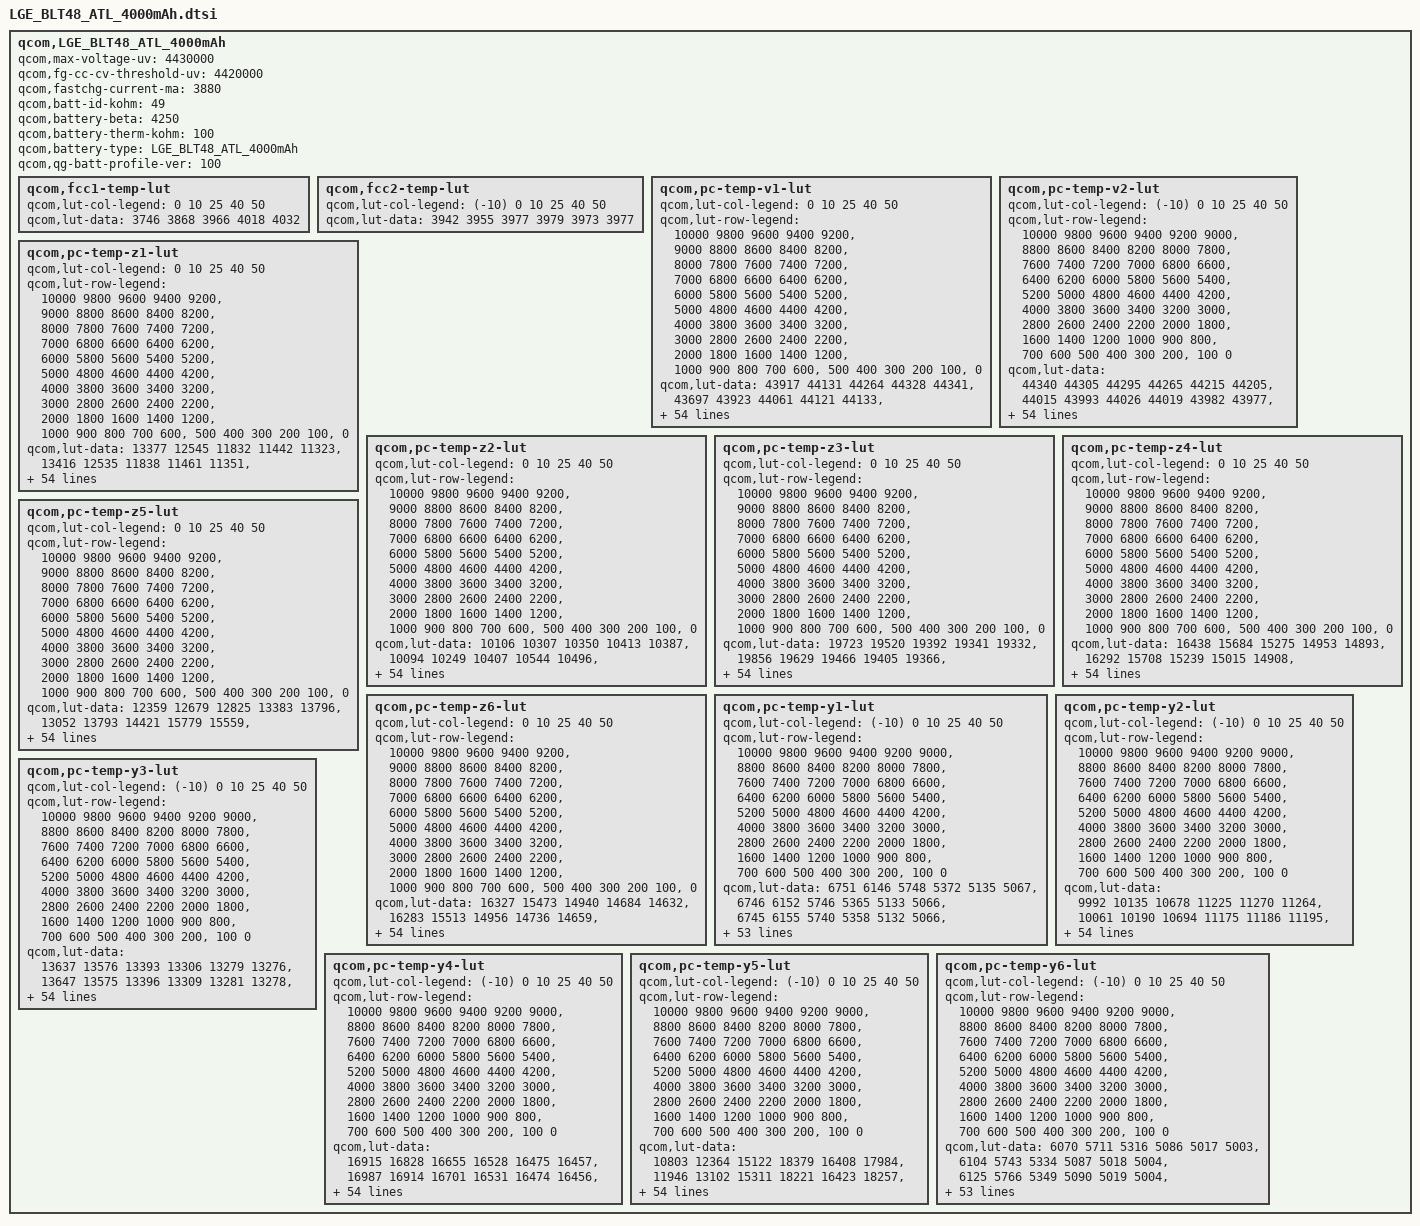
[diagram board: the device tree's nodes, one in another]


qcom,LGE_BLT48_ATL_4000mAh {
    /* 4895688_LGE_ATL_4500mAh_averaged_MasterSlave_Nov23rd2020 */
    qcom,max-voltage-uv = <4430000>;
    qcom,fg-cc-cv-threshold-uv = <4420000>;
    qcom,fastchg-current-ma = <3880>;
    qcom,batt-id-kohm = <49>;
    qcom,battery-beta = <4250>;
    qcom,battery-therm-kohm = <100>;
    qcom,battery-type = "LGE_BLT48_ATL_4000mAh";
    qcom,qg-batt-profile-ver = <100>;

	qcom,fcc1-temp-lut {
		qcom,lut-col-legend = <0 10 25 40 50>;
		qcom,lut-data = <3746 3868 3966 4018 4032>;
	};

	qcom,fcc2-temp-lut {
		qcom,lut-col-legend = <(-10) 0 10 25 40 50>;
		qcom,lut-data = <3942 3955 3977 3979 3973 3977>;
	};

	qcom,pc-temp-v1-lut {
		qcom,lut-col-legend = <0 10 25 40 50>;
		qcom,lut-row-legend = <10000 9800 9600 9400 9200>,
			<9000 8800 8600 8400 8200>,
			<8000 7800 7600 7400 7200>,
			<7000 6800 6600 6400 6200>,
			<6000 5800 5600 5400 5200>,
			<5000 4800 4600 4400 4200>,
			<4000 3800 3600 3400 3200>,
			<3000 2800 2600 2400 2200>,
			<2000 1800 1600 1400 1200>,
			<1000 900 800 700 600>,
			<500 400 300 200 100>,
			<0>;
		qcom,lut-data = <43917 44131 44264 44328 44341>,
			<43697 43923 44061 44121 44133>,
			<43472 43713 43854 43925 43935>,
			<43244 43499 43646 43723 43734>,
			<43013 43274 43434 43516 43527>,
			<42780 43038 43211 43301 43313>,
			<42545 42799 42974 43071 43088>,
			<42309 42559 42732 42831 42853>,
			<42079 42318 42489 42588 42613>,
			<41852 42080 42242 42343 42368>,
			<41630 41844 42000 42099 42122>,
			<41413 41613 41761 41857 41882>,
			<41200 41390 41527 41617 41645>,
			<40996 41174 41298 41384 41412>,
			<40799 40963 41075 41158 41182>,
			<40606 40760 40861 40939 40958>,
			<40407 40563 40655 40726 40743>,
			<40206 40374 40457 40520 40535>,
			<40023 40190 40276 40325 40338>,
			<39869 40009 40103 40147 40159>,
			<39728 39830 39905 39961 39977>,
			<39577 39650 39648 39726 39754>,
			<39415 39439 39393 39466 39505>,
			<39249 39170 39200 39257 39292>,
			<39077 38946 39037 39092 39116>,
			<38898 38827 38903 38947 38962>,
			<38751 38743 38797 38818 38826>,
			<38648 38667 38703 38702 38706>,
			<38564 38595 38610 38597 38596>,
			<38496 38528 38518 38499 38497>,
			<38443 38465 38438 38410 38407>,
			<38396 38404 38365 38329 38321>,
			<38354 38349 38301 38255 38242>,
			<38317 38297 38243 38188 38169>,
			<38280 38251 38193 38129 38107>,
			<38246 38209 38143 38072 38044>,
			<38210 38174 38096 38013 37973>,
			<38164 38132 38046 37952 37896>,
			<38098 38061 37977 37879 37812>,
			<38015 37963 37883 37789 37721>,
			<37912 37855 37778 37687 37619>,
			<37780 37734 37660 37572 37499>,
			<37629 37591 37524 37439 37363>,
			<37463 37417 37357 37274 37203>,
			<37329 37262 37201 37126 37060>,
			<37223 37160 37098 37031 36968>,
			<37190 37132 37072 37008 36949>,
			<37160 37104 37055 36994 36933>,
			<37128 37078 37033 36976 36915>,
			<37079 37040 36998 36932 36867>,
			<36908 36855 36785 36698 36611>,
			<36480 36420 36358 36268 36179>,
			<35913 35853 35793 35700 35611>,
			<35146 35078 35022 34927 34837>,
			<33897 33841 33828 33736 33651>,
			<30000 30000 30000 30000 30000>;
	};

	qcom,pc-temp-v2-lut {
		qcom,lut-col-legend = <(-10) 0 10 25 40 50>;
		qcom,lut-row-legend = <10000 9800 9600 9400 9200 9000>,
			<8800 8600 8400 8200 8000 7800>,
			<7600 7400 7200 7000 6800 6600>,
			<6400 6200 6000 5800 5600 5400>,
			<5200 5000 4800 4600 4400 4200>,
			<4000 3800 3600 3400 3200 3000>,
			<2800 2600 2400 2200 2000 1800>,
			<1600 1400 1200 1000 900 800>,
			<700 600 500 400 300 200>,
			<100 0>;
		qcom,lut-data = <44340 44305 44295 44265 44215 44205>,
			<44015 43993 44026 44019 43982 43977>,
			<43719 43705 43770 43783 43753 43753>,
			<43456 43446 43533 43557 43532 43534>,
			<43227 43217 43314 43343 43319 43322>,
			<43001 42987 43092 43125 43101 43104>,
			<42756 42740 42852 42890 42869 42873>,
			<42506 42486 42607 42648 42629 42634>,
			<42269 42236 42360 42406 42389 42395>,
			<42051 41992 42111 42163 42146 42153>,
			<41820 41743 41865 41921 41906 41913>,
			<41526 41460 41624 41682 41669 41676>,
			<41204 41173 41387 41447 41436 41443>,
			<40975 40988 41161 41216 41208 41214>,
			<40841 40887 40944 40992 40985 40990>,
			<40696 40774 40738 40774 40768 40772>,
			<40415 40524 40550 40565 40560 40564>,
			<40011 40155 40367 40362 40358 40362>,
			<39689 39856 40147 40169 40164 40169>,
			<39462 39634 39867 39990 39983 39990>,
			<39264 39430 39593 39797 39790 39799>,
			<39070 39218 39363 39545 39548 39560>,
			<38886 39010 39156 39265 39282 39299>,
			<38717 38817 38970 39049 39072 39091>,
			<38552 38633 38804 38882 38907 38926>,
			<38407 38465 38654 38739 38766 38782>,
			<38302 38312 38522 38611 38641 38655>,
			<38220 38172 38402 38497 38531 38542>,
			<38147 38079 38282 38391 38428 38438>,
			<38080 38024 38153 38288 38331 38341>,
			<38018 37981 38042 38195 38242 38252>,
			<37957 37936 37960 38112 38162 38170>,
			<37899 37894 37894 38036 38090 38094>,
			<37838 37849 37842 37964 38015 38016>,
			<37773 37802 37806 37896 37938 37936>,
			<37706 37752 37770 37828 37856 37848>,
			<37634 37698 37729 37753 37760 37741>,
			<37558 37641 37684 37673 37652 37618>,
			<37478 37574 37623 37592 37552 37508>,
			<37392 37493 37538 37514 37464 37415>,
			<37304 37398 37434 37429 37374 37322>,
			<37223 37288 37314 37323 37269 37216>,
			<37148 37157 37173 37198 37150 37098>,
			<37074 37022 37018 37046 37009 36956>,
			<36998 36889 36877 36922 36894 36846>,
			<36917 36790 36781 36861 36847 36803>,
			<36866 36759 36747 36843 36836 36791>,
			<36811 36726 36712 36824 36820 36776>,
			<36742 36690 36665 36791 36797 36751>,
			<36654 36622 36570 36713 36723 36665>,
			<36513 36449 36354 36472 36471 36388>,
			<36242 36034 35940 36003 35991 35906>,
			<35773 35380 35303 35369 35373 35281>,
			<35001 34371 34346 34494 34527 34421>,
			<33630 32548 32758 33099 33306 33190>,
			<31039 29548 29509 29507 29507 29506>;
	};

	qcom,pc-temp-z1-lut {
		qcom,lut-col-legend = <0 10 25 40 50>;
		qcom,lut-row-legend = <10000 9800 9600 9400 9200>,
			<9000 8800 8600 8400 8200>,
			<8000 7800 7600 7400 7200>,
			<7000 6800 6600 6400 6200>,
			<6000 5800 5600 5400 5200>,
			<5000 4800 4600 4400 4200>,
			<4000 3800 3600 3400 3200>,
			<3000 2800 2600 2400 2200>,
			<2000 1800 1600 1400 1200>,
			<1000 900 800 700 600>,
			<500 400 300 200 100>,
			<0>;
		qcom,lut-data = <13377 12545 11832 11442 11323>,
			<13416 12535 11838 11461 11351>,
			<13436 12529 11841 11465 11357>,
			<13438 12523 11834 11464 11359>,
			<13440 12522 11820 11460 11357>,
			<13438 12520 11809 11456 11356>,
			<13420 12516 11800 11454 11356>,
			<13397 12507 11791 11453 11356>,
			<13381 12492 11786 11452 11356>,
			<13363 12480 11782 11449 11356>,
			<13346 12468 11779 11447 11355>,
			<13328 12459 11776 11447 11355>,
			<13312 12455 11774 11447 11357>,
			<13307 12453 11776 11447 11359>,
			<13310 12452 11781 11448 11361>,
			<13315 12451 11784 11450 11363>,
			<13323 12450 11785 11452 11365>,
			<13337 12453 11786 11455 11368>,
			<13347 12467 11788 11458 11371>,
			<13344 12475 11792 11460 11374>,
			<13337 12475 11795 11463 11377>,
			<13338 12475 11798 11465 11379>,
			<13358 12478 11802 11468 11382>,
			<13378 12487 11806 11471 11385>,
			<13384 12495 11812 11475 11390>,
			<13388 12499 11817 11480 11395>,
			<13388 12503 11822 11485 11399>,
			<13369 12509 11828 11491 11403>,
			<13341 12517 11836 11496 11407>,
			<13334 12524 11846 11502 11412>,
			<13338 12527 11854 11507 11417>,
			<13345 12531 11859 11512 11421>,
			<13366 12534 11864 11517 11424>,
			<13410 12535 11867 11521 11428>,
			<13436 12535 11871 11526 11432>,
			<13428 12541 11875 11530 11436>,
			<13415 12555 11880 11534 11439>,
			<13414 12567 11886 11538 11442>,
			<13440 12568 11891 11542 11445>,
			<13465 12565 11898 11545 11448>,
			<13474 12570 11905 11548 11451>,
			<13489 12590 11913 11553 11454>,
			<13490 12602 11921 11557 11458>,
			<13484 12602 11924 11562 11461>,
			<13488 12611 11936 11568 11464>,
			<13458 12621 11951 11573 11467>,
			<13453 12615 11951 11574 11467>,
			<13457 12614 11954 11575 11468>,
			<13471 12620 11956 11579 11470>,
			<13477 12648 11953 11581 11472>,
			<13461 12655 11971 11589 11478>,
			<13505 12660 11982 11599 11487>,
			<13530 12710 12011 11613 11500>,
			<13557 12736 12038 11636 11520>,
			<13557 12736 12038 11636 11520>,
			<13557 12736 12038 11636 11520>;
	};

	qcom,pc-temp-z2-lut {
		qcom,lut-col-legend = <0 10 25 40 50>;
		qcom,lut-row-legend = <10000 9800 9600 9400 9200>,
			<9000 8800 8600 8400 8200>,
			<8000 7800 7600 7400 7200>,
			<7000 6800 6600 6400 6200>,
			<6000 5800 5600 5400 5200>,
			<5000 4800 4600 4400 4200>,
			<4000 3800 3600 3400 3200>,
			<3000 2800 2600 2400 2200>,
			<2000 1800 1600 1400 1200>,
			<1000 900 800 700 600>,
			<500 400 300 200 100>,
			<0>;
		qcom,lut-data = <10106 10307 10350 10413 10387>,
			<10094 10249 10407 10544 10496>,
			<10081 10222 10430 10564 10554>,
			<10064 10202 10412 10564 10576>,
			<10047 10174 10367 10513 10546>,
			<10042 10135 10325 10458 10501>,
			<10044 10103 10279 10443 10481>,
			<10046 10084 10251 10435 10470>,
			<10044 10069 10263 10434 10458>,
			<10035 10068 10296 10440 10446>,
			<10028 10088 10317 10447 10431>,
			<10025 10113 10327 10453 10397>,
			<10024 10128 10336 10462 10334>,
			<10025 10141 10348 10461 10308>,
			<10034 10153 10361 10424 10321>,
			<10043 10165 10372 10393 10342>,
			<10042 10178 10383 10401 10363>,
			<10038 10194 10393 10423 10388>,
			<10035 10216 10402 10436 10403>,
			<10049 10229 10411 10448 10409>,
			<10072 10232 10426 10461 10415>,
			<10079 10234 10476 10518 10448>,
			<10077 10238 10522 10618 10526>,
			<10076 10248 10497 10657 10588>,
			<10078 10256 10415 10659 10637>,
			<10089 10254 10380 10657 10667>,
			<10100 10247 10430 10656 10641>,
			<10108 10245 10486 10644 10559>,
			<10115 10248 10487 10611 10483>,
			<10121 10253 10469 10519 10380>,
			<10126 10258 10451 10455 10307>,
			<10131 10265 10434 10462 10312>,
			<10136 10272 10421 10484 10336>,
			<10141 10278 10424 10510 10366>,
			<10147 10284 10445 10549 10409>,
			<10155 10290 10467 10595 10462>,
			<10163 10298 10486 10652 10532>,
			<10174 10307 10506 10714 10615>,
			<10186 10324 10532 10758 10677>,
			<10200 10344 10567 10795 10726>,
			<10214 10350 10583 10814 10764>,
			<10229 10350 10577 10786 10796>,
			<10249 10351 10570 10753 10815>,
			<10276 10366 10566 10768 10687>,
			<10178 10487 10603 10715 10622>,
			<10143 10518 10614 10661 10650>,
			<9967 10532 10596 10653 10633>,
			<9884 10532 10578 10625 10617>,
			<9985 10555 10582 10633 10658>,
			<10021 10716 10609 10729 10777>,
			<9893 10670 10702 10663 10502>,
			<9791 10741 10705 10493 10386>,
			<9692 10664 10767 10439 10334>,
			<9501 10471 10704 10390 10266>,
			<9501 10471 10704 10390 10266>,
			<9501 10471 10704 10390 10266>;
	};

	qcom,pc-temp-z3-lut {
		qcom,lut-col-legend = <0 10 25 40 50>;
		qcom,lut-row-legend = <10000 9800 9600 9400 9200>,
			<9000 8800 8600 8400 8200>,
			<8000 7800 7600 7400 7200>,
			<7000 6800 6600 6400 6200>,
			<6000 5800 5600 5400 5200>,
			<5000 4800 4600 4400 4200>,
			<4000 3800 3600 3400 3200>,
			<3000 2800 2600 2400 2200>,
			<2000 1800 1600 1400 1200>,
			<1000 900 800 700 600>,
			<500 400 300 200 100>,
			<0>;
		qcom,lut-data = <19723 19520 19392 19341 19332>,
			<19856 19629 19466 19405 19366>,
			<19937 19678 19512 19424 19386>,
			<19973 19710 19529 19434 19399>,
			<19995 19728 19539 19442 19410>,
			<19999 19742 19542 19447 19417>,
			<19995 19748 19541 19446 19415>,
			<19990 19746 19537 19441 19405>,
			<19987 19741 19530 19435 19398>,
			<19983 19733 19515 19426 19394>,
			<19977 19718 19504 19417 19391>,
			<19970 19699 19497 19413 19384>,
			<19961 19683 19491 19410 19372>,
			<19949 19666 19486 19405 19366>,
			<19930 19657 19482 19391 19364>,
			<19915 19654 19478 19380 19363>,
			<19911 19652 19472 19378 19361>,
			<19908 19646 19466 19377 19359>,
			<19905 19636 19460 19375 19355>,
			<19888 19630 19453 19373 19348>,
			<19864 19634 19452 19371 19342>,
			<19859 19642 19479 19378 19344>,
			<19879 19651 19507 19393 19353>,
			<19900 19665 19500 19396 19357>,
			<19908 19673 19472 19377 19357>,
			<19912 19669 19458 19362 19358>,
			<19914 19656 19457 19381 19371>,
			<19910 19647 19457 19419 19398>,
			<19902 19642 19465 19429 19405>,
			<19893 19639 19489 19423 19390>,
			<19882 19640 19500 19416 19374>,
			<19871 19643 19498 19409 19369>,
			<19862 19644 19494 19402 19366>,
			<19852 19644 19489 19397 19362>,
			<19843 19642 19482 19393 19354>,
			<19836 19640 19476 19389 19349>,
			<19830 19635 19472 19385 19349>,
			<19821 19628 19469 19381 19349>,
			<19810 19623 19465 19379 19350>,
			<19796 19616 19461 19379 19350>,
			<19782 19609 19456 19378 19352>,
			<19765 19601 19452 19374 19356>,
			<19747 19592 19447 19371 19360>,
			<19721 19582 19439 19371 19353>,
			<19445 19532 19424 19364 19344>,
			<19419 19514 19420 19356 19345>,
			<19317 19494 19419 19355 19335>,
			<19265 19491 19411 19347 19332>,
			<19264 19480 19411 19344 19327>,
			<19264 19432 19391 19337 19324>,
			<19265 19456 19386 19351 19352>,
			<19266 19413 19371 19360 19357>,
			<19267 19341 19347 19362 19357>,
			<19276 19336 19343 19362 19360>,
			<19276 19336 19343 19362 19360>,
			<19276 19336 19343 19362 19360>;
	};

	qcom,pc-temp-z4-lut {
		qcom,lut-col-legend = <0 10 25 40 50>;
		qcom,lut-row-legend = <10000 9800 9600 9400 9200>,
			<9000 8800 8600 8400 8200>,
			<8000 7800 7600 7400 7200>,
			<7000 6800 6600 6400 6200>,
			<6000 5800 5600 5400 5200>,
			<5000 4800 4600 4400 4200>,
			<4000 3800 3600 3400 3200>,
			<3000 2800 2600 2400 2200>,
			<2000 1800 1600 1400 1200>,
			<1000 900 800 700 600>,
			<500 400 300 200 100>,
			<0>;
		qcom,lut-data = <16438 15684 15275 14953 14893>,
			<16292 15708 15239 15015 14908>,
			<16135 15602 15191 14972 14889>,
			<15957 15421 15123 14930 14866>,
			<15775 15295 15041 14892 14836>,
			<15630 15196 14978 14856 14806>,
			<15513 15114 14928 14825 14786>,
			<15413 15048 14888 14798 14771>,
			<15327 14992 14860 14783 14760>,
			<15251 14948 14839 14775 14750>,
			<15184 14909 14824 14768 14743>,
			<15125 14882 14812 14757 14740>,
			<15073 14872 14802 14745 14737>,
			<15029 14868 14791 14740 14734>,
			<14988 14861 14781 14738 14725>,
			<14960 14849 14773 14736 14713>,
			<14955 14837 14767 14730 14704>,
			<14954 14834 14762 14718 14695>,
			<14953 14834 14757 14709 14690>,
			<14944 14833 14752 14701 14687>,
			<14929 14830 14752 14697 14685>,
			<14915 14828 14792 14727 14710>,
			<14898 14840 14851 14797 14779>,
			<14886 14938 14898 14844 14813>,
			<14902 15020 14945 14875 14822>,
			<14959 15016 14961 14891 14827>,
			<14994 14996 14944 14863 14807>,
			<14996 14975 14915 14800 14756>,
			<14997 14953 14882 14768 14735>,
			<14996 14931 14841 14754 14732>,
			<14984 14911 14815 14745 14730>,
			<14966 14892 14803 14735 14722>,
			<14951 14878 14795 14728 14710>,
			<14935 14869 14792 14725 14704>,
			<14920 14862 14790 14723 14702>,
			<14905 14855 14790 14723 14701>,
			<14891 14847 14791 14729 14709>,
			<14878 14843 14794 14742 14725>,
			<14867 14844 14800 14750 14731>,
			<14857 14845 14809 14757 14732>,
			<14849 14844 14813 14761 14733>,
			<14842 14823 14798 14753 14723>,
			<14830 14803 14778 14742 14711>,
			<14814 14788 14770 14740 14721>,
			<14958 14752 14743 14732 14719>,
			<14976 14738 14715 14714 14699>,
			<15073 14741 14701 14701 14693>,
			<15124 14729 14686 14684 14674>,
			<15117 14730 14671 14664 14655>,
			<15102 14771 14681 14667 14654>,
			<15099 14752 14713 14683 14657>,
			<15130 14817 14736 14678 14655>,
			<15145 14904 14760 14675 14654>,
			<15166 14916 14765 14674 14650>,
			<15166 14916 14765 14674 14650>,
			<15166 14916 14765 14674 14650>;
	};

	qcom,pc-temp-z5-lut {
		qcom,lut-col-legend = <0 10 25 40 50>;
		qcom,lut-row-legend = <10000 9800 9600 9400 9200>,
			<9000 8800 8600 8400 8200>,
			<8000 7800 7600 7400 7200>,
			<7000 6800 6600 6400 6200>,
			<6000 5800 5600 5400 5200>,
			<5000 4800 4600 4400 4200>,
			<4000 3800 3600 3400 3200>,
			<3000 2800 2600 2400 2200>,
			<2000 1800 1600 1400 1200>,
			<1000 900 800 700 600>,
			<500 400 300 200 100>,
			<0>;
		qcom,lut-data = <12359 12679 12825 13383 13796>,
			<13052 13793 14421 15779 15559>,
			<13566 14440 15495 16554 16672>,
			<13888 14946 15982 16988 17531>,
			<14139 15460 16294 17262 18380>,
			<14410 15957 16512 17506 18992>,
			<14693 16444 16802 17946 19018>,
			<15003 16937 17051 18483 18857>,
			<15373 17460 17304 18630 18779>,
			<15807 18095 17672 18359 18951>,
			<16289 19054 17811 18104 19158>,
			<16837 19742 17991 18292 18873>,
			<17435 19726 18239 18765 17856>,
			<18028 19583 18554 18845 17400>,
			<18661 19549 19013 17982 17806>,
			<19307 20442 19346 17225 18467>,
			<20023 21528 19723 17459 19139>,
			<20857 21574 19992 18179 19893>,
			<21252 21114 20054 18872 20132>,
			<20805 20825 20284 19477 19723>,
			<20090 23203 21101 20267 19297>,
			<20316 27717 29561 22262 19490>,
			<24926 30737 38283 25027 20057>,
			<30585 33065 35696 25161 20083>,
			<33799 34346 25721 19732 17503>,
			<36380 32446 20096 15240 15033>,
			<37485 27793 18554 16088 16064>,
			<36487 25252 17747 18192 18812>,
			<34468 24316 18347 19435 19684>,
			<32762 23808 20806 20019 18936>,
			<31230 24131 23128 20618 18254>,
			<29943 25549 24909 21531 18785>,
			<29088 27073 26461 22661 20177>,
			<28390 28739 27684 23962 21124>,
			<28093 30306 28765 25748 21773>,
			<28218 30908 29368 26803 22143>,
			<28476 31281 29662 26421 22171>,
			<28712 31462 29795 25458 22094>,
			<29001 31353 29186 24368 21875>,
			<29219 31061 27082 22848 21063>,
			<28810 30615 25595 21659 20473>,
			<27472 29635 25254 21198 21418>,
			<26862 28766 24851 20838 22641>,
			<26481 28211 22964 20302 19861>,
			<17218 26777 23292 19477 18630>,
			<14948 24787 25054 19393 19326>,
			<12059 20957 25557 20072 18148>,
			<11251 20924 24732 20108 19525>,
			<11219 19972 26631 22305 22292>,
			<11210 15553 20844 20751 21446>,
			<11245 17534 17721 18021 22254>,
			<11231 14041 15261 18341 22532>,
			<11134 12107 13518 18230 21536>,
			<11074 11902 13182 17816 22004>,
			<11074 11902 13182 17816 22004>,
			<11074 11902 13182 17816 22004>;
	};

	qcom,pc-temp-z6-lut {
		qcom,lut-col-legend = <0 10 25 40 50>;
		qcom,lut-row-legend = <10000 9800 9600 9400 9200>,
			<9000 8800 8600 8400 8200>,
			<8000 7800 7600 7400 7200>,
			<7000 6800 6600 6400 6200>,
			<6000 5800 5600 5400 5200>,
			<5000 4800 4600 4400 4200>,
			<4000 3800 3600 3400 3200>,
			<3000 2800 2600 2400 2200>,
			<2000 1800 1600 1400 1200>,
			<1000 900 800 700 600>,
			<500 400 300 200 100>,
			<0>;
		qcom,lut-data = <16327 15473 14940 14684 14632>,
			<16283 15513 14956 14736 14659>,
			<16222 15469 14959 14733 14663>,
			<16137 15391 14943 14728 14664>,
			<16036 15332 14905 14716 14658>,
			<15951 15283 14873 14701 14648>,
			<15877 15238 14849 14687 14639>,
			<15811 15198 14827 14673 14627>,
			<15756 15162 14807 14662 14618>,
			<15708 15130 14789 14653 14612>,
			<15664 15099 14776 14646 14608>,
			<15624 15075 14767 14639 14602>,
			<15587 15060 14758 14633 14595>,
			<15555 15048 14751 14626 14589>,
			<15523 15040 14745 14619 14584>,
			<15501 15032 14739 14612 14579>,
			<15498 15026 14734 14606 14574>,
			<15497 15021 14729 14602 14569>,
			<15496 15017 14723 14597 14565>,
			<15484 15016 14719 14593 14560>,
			<15467 15017 14719 14591 14556>,
			<15462 15022 14752 14609 14568>,
			<15467 15034 14793 14649 14603>,
			<15476 15085 14806 14667 14621>,
			<15492 15126 14814 14672 14628>,
			<15521 15123 14816 14674 14631>,
			<15538 15110 14809 14672 14629>,
			<15538 15099 14798 14666 14624>,
			<15537 15088 14792 14659 14617>,
			<15536 15079 14787 14651 14609>,
			<15528 15073 14782 14643 14601>,
			<15516 15068 14778 14637 14595>,
			<15508 15065 14774 14631 14589>,
			<15499 15063 14770 14627 14584>,
			<15493 15062 14766 14623 14579>,
			<15487 15061 14765 14622 14576>,
			<15483 15059 14765 14623 14579>,
			<15479 15058 14766 14627 14586>,
			<15476 15059 14767 14630 14589>,
			<15473 15062 14770 14632 14591>,
			<15470 15062 14772 14634 14592>,
			<15468 15054 14765 14629 14590>,
			<15464 15048 14756 14624 14588>,
			<15456 15044 14751 14624 14588>,
			<15398 15017 14737 14617 14584>,
			<15395 15007 14725 14606 14576>,
			<15389 14999 14719 14600 14569>,
			<15388 14996 14709 14589 14559>,
			<15390 14993 14704 14579 14548>,
			<15393 14992 14700 14577 14545>,
			<15403 15006 14715 14593 14564>,
			<15432 15021 14721 14598 14568>,
			<15457 15035 14725 14601 14570>,
			<15500 15059 14734 14605 14575>,
			<15500 15059 14734 14605 14575>,
			<15500 15059 14734 14605 14575>;
	};

	qcom,pc-temp-y1-lut {
		qcom,lut-col-legend = <(-10) 0 10 25 40 50>;
		qcom,lut-row-legend = <10000 9800 9600 9400 9200 9000>,
			<8800 8600 8400 8200 8000 7800>,
			<7600 7400 7200 7000 6800 6600>,
			<6400 6200 6000 5800 5600 5400>,
			<5200 5000 4800 4600 4400 4200>,
			<4000 3800 3600 3400 3200 3000>,
			<2800 2600 2400 2200 2000 1800>,
			<1600 1400 1200 1000 900 800>,
			<700 600 500 400 300 200>,
			<100 0>;
		qcom,lut-data = <6751 6146 5748 5372 5135 5067>,
			<6746 6152 5746 5365 5133 5066>,
			<6745 6155 5740 5358 5132 5066>,
			<6749 6156 5732 5351 5131 5065>,
			<6753 6156 5726 5346 5129 5064>,
			<6755 6155 5722 5341 5128 5064>,
			<6759 6148 5719 5337 5126 5063>,
			<6767 6137 5717 5334 5125 5062>,
			<6774 6132 5717 5332 5123 5062>,
			<6788 6129 5716 5330 5122 5061>,
			<6799 6127 5715 5329 5120 5061>,
			<6786 6133 5708 5326 5120 5061>,
			<6758 6145 5700 5323 5119 5061>,
			<6748 6154 5699 5322 5119 5061>,
			<6763 6167 5705 5322 5119 5062>,
			<6779 6175 5710 5323 5119 5063>,
			<6783 6171 5713 5324 5119 5064>,
			<6790 6160 5715 5326 5121 5065>,
			<6792 6157 5717 5326 5122 5066>,
			<6785 6168 5720 5327 5122 5067>,
			<6779 6180 5724 5328 5123 5068>,
			<6780 6183 5730 5330 5125 5069>,
			<6783 6184 5738 5334 5127 5070>,
			<6787 6185 5739 5337 5129 5072>,
			<6785 6192 5735 5340 5131 5074>,
			<6781 6198 5732 5344 5132 5076>,
			<6783 6195 5740 5348 5135 5078>,
			<6793 6186 5755 5353 5138 5080>,
			<6802 6182 5760 5358 5142 5082>,
			<6803 6190 5755 5364 5145 5085>,
			<6802 6199 5751 5369 5149 5088>,
			<6801 6200 5754 5372 5151 5090>,
			<6797 6203 5761 5373 5154 5093>,
			<6791 6205 5764 5376 5157 5095>,
			<6782 6213 5768 5384 5161 5098>,
			<6773 6223 5771 5392 5165 5101>,
			<6776 6223 5770 5397 5167 5103>,
			<6794 6216 5771 5401 5170 5104>,
			<6810 6215 5776 5403 5172 5106>,
			<6814 6228 5782 5406 5174 5108>,
			<6818 6244 5787 5408 5177 5110>,
			<6822 6246 5793 5413 5179 5112>,
			<6836 6241 5801 5423 5182 5114>,
			<6842 6244 5804 5437 5186 5117>,
			<6855 6254 5813 5447 5189 5119>,
			<6854 6266 5840 5441 5193 5123>,
			<6883 6261 5834 5441 5195 5123>,
			<6913 6290 5830 5458 5196 5123>,
			<6962 6325 5843 5462 5197 5124>,
			<7015 6315 5858 5468 5196 5124>,
			<7054 6331 5881 5471 5198 5127>,
			<7124 6375 5900 5481 5207 5133>,
			<7243 6421 5938 5514 5218 5141>,
			<7390 6550 6008 5536 5232 5153>,
			<7390 6550 6008 5536 5232 5153>,
			<7390 6550 6008 5536 5232 5153>;
	};

	qcom,pc-temp-y2-lut {
		qcom,lut-col-legend = <(-10) 0 10 25 40 50>;
		qcom,lut-row-legend = <10000 9800 9600 9400 9200 9000>,
			<8800 8600 8400 8200 8000 7800>,
			<7600 7400 7200 7000 6800 6600>,
			<6400 6200 6000 5800 5600 5400>,
			<5200 5000 4800 4600 4400 4200>,
			<4000 3800 3600 3400 3200 3000>,
			<2800 2600 2400 2200 2000 1800>,
			<1600 1400 1200 1000 900 800>,
			<700 600 500 400 300 200>,
			<100 0>;
		qcom,lut-data = <9992 10135 10678 11225 11270 11264>,
			<10061 10190 10694 11175 11186 11195>,
			<10134 10256 10717 11126 11111 11119>,
			<10203 10322 10741 11081 11051 11045>,
			<10262 10377 10760 11041 11009 10983>,
			<10304 10411 10767 11010 10992 10941>,
			<10326 10428 10765 10985 11005 10915>,
			<10342 10438 10762 10966 11026 10897>,
			<10372 10445 10762 10955 11025 10902>,
			<10434 10449 10766 10946 11013 10946>,
			<10494 10457 10769 10942 11006 10977>,
			<10531 10514 10765 10950 11010 10968>,
			<10560 10617 10758 10969 11021 10953>,
			<10585 10661 10769 10995 11037 10953>,
			<10609 10669 10865 11036 11065 10985>,
			<10629 10679 10969 11080 11102 11027>,
			<10554 10723 11040 11116 11147 11067>,
			<10343 10801 11096 11153 11202 11113>,
			<10235 10874 11104 11204 11269 11184>,
			<9980 10953 11072 11287 11371 11319>,
			<9722 11004 11046 11339 11436 11409>,
			<9696 10987 11051 11302 11411 11379>,
			<9692 10925 11063 11231 11354 11312>,
			<9688 10860 11077 11214 11320 11277>,
			<9683 10805 11096 11232 11297 11248>,
			<9678 10726 11115 11256 11284 11234>,
			<9675 10459 11128 11276 11329 11251>,
			<9673 9933 11140 11298 11431 11286>,
			<9671 9705 11135 11320 11488 11347>,
			<9670 9692 11069 11345 11510 11508>,
			<9669 9685 11007 11367 11532 11648>,
			<9668 9679 11000 11384 11581 11683>,
			<9666 9675 10997 11398 11648 11702>,
			<9665 9671 10989 11400 11669 11714>,
			<9665 9668 10956 11388 11660 11724>,
			<9664 9666 10909 11371 11644 11729>,
			<9664 9664 10864 11349 11612 11683>,
			<9663 9663 10808 11312 11553 11559>,
			<9662 9662 10694 11276 11503 11477>,
			<9662 9661 10299 11237 11451 11417>,
			<9662 9661 9908 11194 11409 11377>,
			<9661 9660 9773 11143 11387 11368>,
			<9661 9660 9700 11082 11358 11355>,
			<9661 9659 9681 10999 11318 11307>,
			<9659 9659 9671 10914 11241 11213>,
			<9658 9658 9668 10904 11140 11105>,
			<9657 9657 9668 10914 11153 11061>,
			<9656 9657 9664 10894 11165 11062>,
			<9654 9656 9662 10873 11156 11122>,
			<9652 9655 9660 10854 11160 11104>,
			<9650 9652 9657 10815 11130 11056>,
			<9648 9650 9655 10728 11036 10962>,
			<9647 9648 9653 10634 10981 10872>,
			<9647 9650 9652 10524 10926 10801>,
			<9647 9650 9652 10524 10926 10801>,
			<9647 9650 9652 10524 10926 10801>;
	};

	qcom,pc-temp-y3-lut {
		qcom,lut-col-legend = <(-10) 0 10 25 40 50>;
		qcom,lut-row-legend = <10000 9800 9600 9400 9200 9000>,
			<8800 8600 8400 8200 8000 7800>,
			<7600 7400 7200 7000 6800 6600>,
			<6400 6200 6000 5800 5600 5400>,
			<5200 5000 4800 4600 4400 4200>,
			<4000 3800 3600 3400 3200 3000>,
			<2800 2600 2400 2200 2000 1800>,
			<1600 1400 1200 1000 900 800>,
			<700 600 500 400 300 200>,
			<100 0>;
		qcom,lut-data = <13637 13576 13393 13306 13279 13276>,
			<13647 13575 13396 13309 13281 13278>,
			<13653 13573 13399 13312 13283 13279>,
			<13657 13572 13402 13315 13285 13281>,
			<13658 13570 13404 13317 13287 13283>,
			<13659 13569 13406 13319 13288 13284>,
			<13654 13568 13408 13320 13290 13286>,
			<13645 13567 13410 13321 13292 13287>,
			<13642 13564 13410 13322 13293 13288>,
			<13641 13558 13410 13324 13294 13290>,
			<13639 13548 13409 13325 13295 13291>,
			<13601 13517 13405 13324 13297 13291>,
			<13523 13470 13397 13324 13299 13292>,
			<13500 13458 13390 13323 13300 13292>,
			<13516 13472 13382 13322 13302 13292>,
			<13532 13484 13378 13321 13303 13292>,
			<13521 13479 13383 13319 13304 13294>,
			<13493 13465 13394 13316 13305 13296>,
			<13482 13451 13395 13316 13305 13297>,
			<13482 13438 13382 13322 13302 13296>,
			<13482 13425 13369 13326 13298 13296>,
			<13484 13410 13363 13322 13294 13292>,
			<13488 13394 13359 13312 13290 13285>,
			<13490 13389 13355 13307 13287 13282>,
			<13484 13390 13351 13305 13284 13280>,
			<13477 13391 13347 13304 13283 13279>,
			<13479 13387 13343 13305 13284 13279>,
			<13492 13375 13340 13305 13286 13280>,
			<13509 13371 13339 13305 13286 13280>,
			<13534 13384 13339 13304 13285 13281>,
			<13566 13407 13340 13303 13284 13281>,
			<13599 13434 13338 13302 13284 13281>,
			<13635 13470 13336 13302 13286 13280>,
			<13674 13508 13335 13302 13287 13280>,
			<13714 13546 13339 13303 13286 13281>,
			<13756 13588 13345 13304 13286 13281>,
			<13800 13637 13349 13304 13285 13280>,
			<13846 13696 13353 13303 13284 13278>,
			<13890 13751 13358 13303 13283 13277>,
			<13927 13799 13365 13303 13283 13277>,
			<13963 13842 13375 13304 13282 13278>,
			<14001 13876 13395 13305 13282 13278>,
			<14043 13905 13428 13307 13282 13280>,
			<14095 13938 13470 13309 13282 13279>,
			<14168 13977 13526 13313 13282 13279>,
			<14299 14029 13549 13315 13286 13284>,
			<14274 14025 13553 13315 13288 13285>,
			<14406 14090 13622 13320 13291 13287>,
			<14747 14214 13707 13327 13298 13292>,
			<15353 14425 13827 13334 13299 13291>,
			<16632 14915 13971 13334 13294 13287>,
			<19720 16048 14162 13335 13291 13287>,
			<29119 19323 14624 13345 13296 13289>,
			<64071 30619 15897 13362 13302 13292>,
			<64071 30619 15897 13362 13302 13292>,
			<64071 30619 15897 13362 13302 13292>;
	};

	qcom,pc-temp-y4-lut {
		qcom,lut-col-legend = <(-10) 0 10 25 40 50>;
		qcom,lut-row-legend = <10000 9800 9600 9400 9200 9000>,
			<8800 8600 8400 8200 8000 7800>,
			<7600 7400 7200 7000 6800 6600>,
			<6400 6200 6000 5800 5600 5400>,
			<5200 5000 4800 4600 4400 4200>,
			<4000 3800 3600 3400 3200 3000>,
			<2800 2600 2400 2200 2000 1800>,
			<1600 1400 1200 1000 900 800>,
			<700 600 500 400 300 200>,
			<100 0>;
		qcom,lut-data = <16915 16828 16655 16528 16475 16457>,
			<16987 16914 16701 16531 16474 16456>,
			<17081 17020 16762 16536 16473 16454>,
			<17176 17125 16823 16541 16473 16453>,
			<17251 17206 16870 16546 16472 16451>,
			<17284 17241 16889 16547 16472 16451>,
			<17276 17230 16883 16547 16472 16451>,
			<17259 17207 16872 16546 16473 16452>,
			<17244 17195 16863 16546 16474 16452>,
			<17227 17188 16855 16548 16477 16454>,
			<17217 17184 16851 16551 16481 16457>,
			<17243 17198 16858 16557 16485 16461>,
			<17300 17234 16874 16568 16489 16466>,
			<17319 17270 16896 16580 16492 16472>,
			<17318 17319 16932 16595 16498 16480>,
			<17313 17352 16955 16613 16506 16488>,
			<17244 17280 16952 16639 16516 16494>,
			<17078 17109 16941 16668 16530 16501>,
			<16999 17012 16918 16680 16549 16512>,
			<16987 16974 16851 16684 16583 16538>,
			<16977 16943 16782 16687 16606 16555>,
			<16945 16902 16741 16647 16577 16536>,
			<16885 16857 16708 16567 16514 16496>,
			<16843 16804 16683 16534 16487 16475>,
			<16818 16719 16662 16522 16479 16465>,
			<16804 16654 16647 16517 16475 16460>,
			<16805 16656 16638 16518 16476 16462>,
			<16816 16675 16631 16522 16480 16467>,
			<16822 16688 16616 16527 16486 16473>,
			<16820 16696 16571 16533 16497 16480>,
			<16816 16703 16537 16539 16511 16489>,
			<16814 16707 16537 16548 16522 16501>,
			<16812 16714 16540 16557 16533 16515>,
			<16811 16722 16545 16559 16536 16519>,
			<16812 16736 16565 16556 16535 16519>,
			<16813 16751 16592 16551 16534 16519>,
			<16813 16761 16617 16539 16522 16509>,
			<16810 16769 16645 16520 16496 16488>,
			<16808 16772 16669 16514 16483 16477>,
			<16811 16772 16694 16516 16479 16473>,
			<16818 16770 16710 16520 16477 16470>,
			<16826 16763 16712 16527 16477 16467>,
			<16838 16739 16713 16535 16479 16464>,
			<16857 16715 16703 16537 16472 16455>,
			<16886 16699 16693 16538 16464 16449>,
			<16908 16705 16687 16530 16467 16451>,
			<16856 16695 16687 16531 16473 16459>,
			<16882 16711 16710 16548 16484 16475>,
			<16985 16731 16741 16570 16501 16499>,
			<17152 16795 16780 16593 16513 16505>,
			<17440 16926 16807 16584 16489 16469>,
			<18060 17159 16846 16573 16467 16453>,
			<20549 18337 17038 16589 16472 16456>,
			<46299 30048 18034 16636 16491 16474>,
			<46299 30048 18034 16636 16491 16474>,
			<46299 30048 18034 16636 16491 16474>;
	};

	qcom,pc-temp-y5-lut {
		qcom,lut-col-legend = <(-10) 0 10 25 40 50>;
		qcom,lut-row-legend = <10000 9800 9600 9400 9200 9000>,
			<8800 8600 8400 8200 8000 7800>,
			<7600 7400 7200 7000 6800 6600>,
			<6400 6200 6000 5800 5600 5400>,
			<5200 5000 4800 4600 4400 4200>,
			<4000 3800 3600 3400 3200 3000>,
			<2800 2600 2400 2200 2000 1800>,
			<1600 1400 1200 1000 900 800>,
			<700 600 500 400 300 200>,
			<100 0>;
		qcom,lut-data = <10803 12364 15122 18379 16408 17984>,
			<11946 13102 15311 18221 16423 18257>,
			<13055 13810 15504 18022 16396 18557>,
			<14085 14469 15696 17790 16348 18835>,
			<14989 15058 15883 17534 16301 19040>,
			<15722 15559 16060 17260 16280 19124>,
			<16234 16027 16267 16949 16267 19097>,
			<16663 16413 16450 16619 16231 19025>,
			<17319 16535 16466 16338 16139 18896>,
			<18504 16532 16329 16097 15809 18567>,
			<19302 16460 16119 15808 15496 18129>,
			<17910 15587 15741 15325 15475 17582>,
			<14935 14005 15245 14741 15629 16912>,
			<14327 13895 14957 14319 15659 16239>,
			<18142 16988 14764 13939 15468 15447>,
			<21665 19640 14672 13743 15241 15001>,
			<20689 19604 16707 13775 15032 15068>,
			<17699 19334 20441 13882 14807 15216>,
			<16070 19307 21322 14557 14773 15300>,
			<15264 20075 20755 18352 14975 15343>,
			<14760 20944 20308 21243 15337 15412>,
			<14834 21262 20496 21073 16616 16561>,
			<14949 21463 20934 20582 18660 18662>,
			<14960 21960 21235 20149 19114 19183>,
			<14048 24473 21407 19688 18015 18659>,
			<12871 26859 21613 19416 17078 17992>,
			<12454 24091 22026 19587 17241 17324>,
			<12218 15793 22665 19936 17637 16615>,
			<12140 12236 23397 19982 17688 16406>,
			<12243 12410 24528 19498 16924 16401>,
			<12442 12674 25298 19091 16237 16397>,
			<12680 12944 23431 19237 16618 16309>,
			<13012 13377 19294 19716 17647 16152>,
			<13279 13675 17910 20454 18285 16182>,
			<13443 13806 17859 22195 18543 17093>,
			<13563 13924 17822 23513 18804 18044>,
			<13618 14150 17767 23086 19430 18352>,
			<13651 14521 17683 21788 20328 18568>,
			<13665 14711 17487 20515 20556 18586>,
			<13416 14676 16591 19201 19435 18204>,
			<12963 14600 15522 18011 18051 17848>,
			<12783 14547 14793 17111 17094 17982>,
			<12754 14469 14272 16466 16178 18352>,
			<12743 14323 14282 16273 16644 19032>,
			<12708 14004 14315 16475 17240 19671>,
			<12973 13430 14052 17496 16940 19291>,
			<13097 13590 14059 17075 16255 17869>,
			<12952 13578 14131 16781 16516 17843>,
			<12397 13913 14188 16668 18197 18484>,
			<11798 13468 14207 17557 18329 17710>,
			<11094 12550 14382 18359 18040 18618>,
			<10108 11304 13986 18665 18422 20705>,
			<9274 9925 12296 18766 20258 21151>,
			<8854 9009 10473 18536 23984 23728>,
			<8854 9009 10473 18536 23984 23728>,
			<8854 9009 10473 18536 23984 23728>;
	};

	qcom,pc-temp-y6-lut {
		qcom,lut-col-legend = <(-10) 0 10 25 40 50>;
		qcom,lut-row-legend = <10000 9800 9600 9400 9200 9000>,
			<8800 8600 8400 8200 8000 7800>,
			<7600 7400 7200 7000 6800 6600>,
			<6400 6200 6000 5800 5600 5400>,
			<5200 5000 4800 4600 4400 4200>,
			<4000 3800 3600 3400 3200 3000>,
			<2800 2600 2400 2200 2000 1800>,
			<1600 1400 1200 1000 900 800>,
			<700 600 500 400 300 200>,
			<100 0>;
		qcom,lut-data = <6070 5711 5316 5086 5017 5003>,
			<6104 5743 5334 5087 5018 5004>,
			<6125 5766 5349 5090 5019 5004>,
			<6136 5781 5360 5092 5020 5005>,
			<6140 5790 5366 5094 5022 5006>,
			<6141 5793 5369 5095 5023 5007>,
			<6132 5788 5366 5095 5024 5008>,
			<6114 5776 5360 5095 5025 5009>,
			<6106 5766 5354 5095 5026 5011>,
			<6104 5756 5348 5096 5028 5012>,
			<6102 5745 5343 5097 5030 5014>,
			<6080 5729 5340 5098 5032 5016>,
			<6042 5712 5337 5100 5034 5018>,
			<6031 5710 5337 5103 5037 5020>,
			<6046 5736 5340 5106 5039 5022>,
			<6060 5759 5343 5110 5042 5024>,
			<6037 5739 5346 5115 5046 5027>,
			<5974 5689 5349 5121 5050 5031>,
			<5941 5658 5346 5126 5055 5035>,
			<5931 5643 5319 5131 5062 5041>,
			<5925 5631 5290 5134 5066 5045>,
			<5919 5620 5276 5120 5056 5037>,
			<5914 5611 5266 5090 5035 5020>,
			<5912 5603 5257 5078 5025 5012>,
			<5913 5594 5250 5074 5021 5008>,
			<5916 5588 5245 5073 5019 5006>,
			<5923 5588 5245 5073 5020 5007>,
			<5946 5590 5246 5076 5022 5009>,
			<5972 5594 5245 5078 5025 5011>,
			<5998 5625 5240 5080 5028 5014>,
			<6026 5673 5236 5082 5031 5017>,
			<6057 5717 5239 5085 5035 5021>,
			<6091 5766 5247 5088 5040 5024>,
			<6127 5816 5258 5090 5041 5026>,
			<6163 5867 5281 5091 5041 5026>,
			<6199 5920 5311 5091 5040 5026>,
			<6236 5974 5343 5089 5037 5023>,
			<6273 6031 5381 5085 5029 5016>,
			<6310 6083 5421 5083 5025 5012>,
			<6345 6128 5462 5086 5024 5011>,
			<6381 6167 5507 5090 5024 5011>,
			<6421 6196 5556 5096 5024 5011>,
			<6466 6218 5611 5104 5024 5011>,
			<6523 6243 5678 5111 5023 5009>,
			<6599 6276 5759 5120 5021 5007>,
			<6749 6334 5794 5120 5026 5012>,
			<6724 6328 5799 5119 5029 5015>,
			<6871 6405 5882 5131 5035 5021>,
			<7235 6520 5983 5145 5045 5032>,
			<7836 6741 6114 5161 5049 5033>,
			<8974 7232 6261 5163 5038 5020>,
			<11536 8257 6465 5168 5031 5016>,
			<18899 11073 6955 5200 5037 5019>,
			<48585 22571 8256 5252 5049 5028>,
			<48585 22571 8256 5252 5049 5028>,
			<48585 22571 8256 5252 5049 5028>;
	};

};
